AUTOSAR XML (schema 4-2-2)
package /SUM_APPLICATION
  sender receiver interface SR_R_SUM_INTERFACE
    data VAL1: type=uint32
    data VAL2: type=uint32
  sender receiver interface SR_P_SUM_INTERFACE
    data RESULT: type=uint32
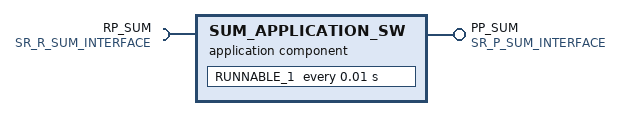
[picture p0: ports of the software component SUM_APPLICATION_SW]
  application sw component type SUM_APPLICATION_SW
    provide port PP_SUM: provided-interface=SR_P_SUM_INTERFACE
    require port RP_SUM: required-interface=SR_R_SUM_INTERFACE
    behavior SUM_RUNNABLES
      timing event ms_time: start-on-event=RUNNABLE_1, period=0.01
      init event INIT_RUN_EVENT: start-on-event=RUNNABLE_1
      data received event DRC_EVENT: start-on-event=RUNNABLE_1, data=VAL1
      data write completed event DWC_EVENT: start-on-event=RUNNABLE_1, event-source=RESULT
      runnable RUNNABLE_1
        data-read-access:
          access VAL1: accessed-variable=RP_SUM.VAL1
          access VAL2: accessed-variable=RP_SUM.VAL2
        data-write-access:
          access RESULT: accessed-variable=PP_SUM.RESULT
